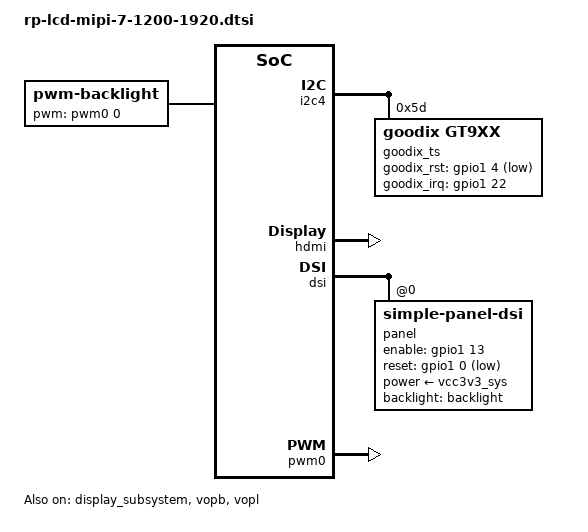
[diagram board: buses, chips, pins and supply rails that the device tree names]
#include <dt-bindings/display/drm_mipi_dsi.h>
/ {

	backlight: backlight {
		status = "okay";
		compatible = "pwm-backlight";
		pwms = <&pwm0 0 25000 0>;
		brightness-levels = <
			  0   1   2   3   4   5   6   7
			  8   9  10  11  12  13  14  15
			 16  17  18  19  20  21  22  23
			 24  25  26  27  28  29  30  31
			 32  33  34  35  36  37  38  39
			 40  41  42  43  44  45  46  47
			 48  49  50  51  52  53  54  55
			 56  57  58  59  60  61  62  63
			 64  65  66  67  68  69  70  71
			 72  73  74  75  76  77  78  79
			 80  81  82  83  84  85  86  87
			 88  89  90  91  92  93  94  95
			 96  97  98  99 100 101 102 103
			104 105 106 107 108 109 110 111
			112 113 114 115 116 117 118 119
			120 121 122 123 124 125 126 127
			128 129 130 131 132 133 134 135
			136 137 138 139 140 141 142 143
			144 145 146 147 148 149 150 151
			152 153 154 155 156 157 158 159
			160 161 162 163 164 165 166 167
			168 169 170 171 172 173 174 175
			176 177 178 179 180 181 182 183
			184 185 186 187 188 189 190 191
			192 193 194 195 196 197 198 199
			200 201 202 203 204 205 206 207
			208 209 210 211 212 213 214 215
			216 217 218 219 220 221 222 223
			224 225 226 227 228 229 230 231
			232 233 234 235 236 237 238 239
			240 241 242 243 244 245 246 247
			248 249 250 251 252 253 254 255>;
		default-brightness-level = <255>;
	};

	//bill  
        rpdzkj_config {
                compatible = "rp_config";
                user_version = "rpdzkj";
                system_rotate = "0";
                back_camera_rotate = "0";
                front_camera_rotate = "0";
                lcd_density = "280";
                language = "zh-CN";   //zh-CN //en-US
                time_zone = "Asia/Shanghai"; //Asia/Shanghai = +8   //Europe/London  = +0
                not_navigation_bar = "false";
                not_status_bar = "false";
                default_launcher = "true";
                has_root = "true";  //true//false
                usb_not_permission = "true";  
                usb_camera_only_front = "false";
                gps_use = "true";
                gps_serial_port = "/dev/ttyS4"; //UART4
                status = "okay";
        };
};




&i2c4 {
        status = "okay";
        goodix_ts@5d {
                compatible = "goodix,gt9xx";
                reg = <0x5d>;
								
		goodix_rst_gpio = <&gpio1 4 GPIO_ACTIVE_LOW>;
		goodix_irq_gpio = <&gpio1 22 IRQ_TYPE_EDGE_RISING>;

	        goodix,cfg-group0 = [
                	5C B0 04 80 07 05 45 00 02 08
									28 08 46 32 03 05 00 00 00 00
									00 00 00 00 00 00 00 8C 2C 0E
									22 24 BB 0A 00 00 02 01 03 1C
									00 01 00 00 00 00 00 32 00 00
									00 14 46 94 C5 02 00 00 00 04
									E3 16 00 B4 1D 00 8D 25 00 72
									30 00 5D 3E 00 5D 00 00 00 00
									00 00 00 00 00 00 00 00 00 00
									00 00 00 00 00 00 00 00 00 00
									00 00 00 00 00 00 00 00 00 00
									00 00 02 04 06 08 0A 0C 0E 10
									12 14 16 18 1A 1C FF FF FF FF
									FF FF FF FF FF FF FF FF FF FF
									FF FF 00 02 04 06 08 0A 0C 0F
									10 12 13 14 28 26 24 22 21 20
									1F 1E 1D 1C 18 16 FF FF FF FF
									FF 00 00 00 00 00 00 00 00 00
									00 00 00 00 B8 01];	
	        goodix,cfg-group1 = [
	                5C B0 04 80 07 05 45 00 02 08
									28 08 46 32 03 05 00 00 00 00
									00 00 00 00 00 00 00 8C 2C 0E
									22 24 BB 0A 00 00 02 01 03 1C
									00 01 00 00 00 00 00 32 00 00
									00 14 46 94 C5 02 00 00 00 04
									E3 16 00 B4 1D 00 8D 25 00 72
									30 00 5D 3E 00 5D 00 00 00 00
									00 00 00 00 00 00 00 00 00 00
									00 00 00 00 00 00 00 00 00 00
									00 00 00 00 00 00 00 00 00 00
									00 00 02 04 06 08 0A 0C 0E 10
									12 14 16 18 1A 1C FF FF FF FF
									FF FF FF FF FF FF FF FF FF FF
									FF FF 00 02 04 06 08 0A 0C 0F
									10 12 13 14 28 26 24 22 21 20
									1F 1E 1D 1C 18 16 FF FF FF FF
									FF 00 00 00 00 00 00 00 00 00
									00 00 00 00 B8 01];	
	        goodix,cfg-group2 = [
	                5C B0 04 80 07 05 45 00 02 08
									28 08 46 32 03 05 00 00 00 00
									00 00 00 00 00 00 00 8C 2C 0E
									22 24 BB 0A 00 00 02 01 03 1C
									00 01 00 00 00 00 00 32 00 00
									00 14 46 94 C5 02 00 00 00 04
									E3 16 00 B4 1D 00 8D 25 00 72
									30 00 5D 3E 00 5D 00 00 00 00
									00 00 00 00 00 00 00 00 00 00
									00 00 00 00 00 00 00 00 00 00
									00 00 00 00 00 00 00 00 00 00
									00 00 02 04 06 08 0A 0C 0E 10
									12 14 16 18 1A 1C FF FF FF FF
									FF FF FF FF FF FF FF FF FF FF
									FF FF 00 02 04 06 08 0A 0C 0F
									10 12 13 14 28 26 24 22 21 20
									1F 1E 1D 1C 18 16 FF FF FF FF
									FF 00 00 00 00 00 00 00 00 00
									00 00 00 00 B8 01];	
	        goodix,cfg-group3 = [
	                5C B0 04 80 07 05 45 00 02 08
									28 08 46 32 03 05 00 00 00 00
									00 00 00 00 00 00 00 8C 2C 0E
									22 24 BB 0A 00 00 02 01 03 1C
									00 01 00 00 00 00 00 32 00 00
									00 14 46 94 C5 02 00 00 00 04
									E3 16 00 B4 1D 00 8D 25 00 72
									30 00 5D 3E 00 5D 00 00 00 00
									00 00 00 00 00 00 00 00 00 00
									00 00 00 00 00 00 00 00 00 00
									00 00 00 00 00 00 00 00 00 00
									00 00 02 04 06 08 0A 0C 0E 10
									12 14 16 18 1A 1C FF FF FF FF
									FF FF FF FF FF FF FF FF FF FF
									FF FF 00 02 04 06 08 0A 0C 0F
									10 12 13 14 28 26 24 22 21 20
									1F 1E 1D 1C 18 16 FF FF FF FF
									FF 00 00 00 00 00 00 00 00 00
									00 00 00 00 B8 01];
	
	        goodix,cfg-group4 = [
	                5C B0 04 80 07 05 45 00 02 08
									28 08 46 32 03 05 00 00 00 00
									00 00 00 00 00 00 00 8C 2C 0E
									22 24 BB 0A 00 00 02 01 03 1C
									00 01 00 00 00 00 00 32 00 00
									00 14 46 94 C5 02 00 00 00 04
									E3 16 00 B4 1D 00 8D 25 00 72
									30 00 5D 3E 00 5D 00 00 00 00
									00 00 00 00 00 00 00 00 00 00
									00 00 00 00 00 00 00 00 00 00
									00 00 00 00 00 00 00 00 00 00
									00 00 02 04 06 08 0A 0C 0E 10
									12 14 16 18 1A 1C FF FF FF FF
									FF FF FF FF FF FF FF FF FF FF
									FF FF 00 02 04 06 08 0A 0C 0F
									10 12 13 14 28 26 24 22 21 20
									1F 1E 1D 1C 18 16 FF FF FF FF
									FF 00 00 00 00 00 00 00 00 00
									00 00 00 00 B8 01];


	        goodix,cfg-group5 = [
	                5C B0 04 80 07 05 45 00 02 08
									28 08 46 32 03 05 00 00 00 00
									00 00 00 00 00 00 00 8C 2C 0E
									22 24 BB 0A 00 00 02 01 03 1C
									00 01 00 00 00 00 00 32 00 00
									00 14 46 94 C5 02 00 00 00 04
									E3 16 00 B4 1D 00 8D 25 00 72
									30 00 5D 3E 00 5D 00 00 00 00
									00 00 00 00 00 00 00 00 00 00
									00 00 00 00 00 00 00 00 00 00
									00 00 00 00 00 00 00 00 00 00
									00 00 02 04 06 08 0A 0C 0E 10
									12 14 16 18 1A 1C FF FF FF FF
									FF FF FF FF FF FF FF FF FF FF
									FF FF 00 02 04 06 08 0A 0C 0F
									10 12 13 14 28 26 24 22 21 20
									1F 1E 1D 1C 18 16 FF FF FF FF
									FF 00 00 00 00 00 00 00 00 00
									00 00 00 00 B8 01];

        };
};
&display_subsystem {
	status = "okay";
	ports = <&vopb_out>, <&vopl_out>;
	logo-memory-region = <&drm_logo>;

	route {
		route_hdmi: route-hdmi {
			status = "okay";
			logo,uboot = "logo.bmp";
			logo,kernel = "logo_kernel.bmp";
			logo,mode = "center";
			charge_logo,mode = "center";
			connect = <&vopl_out_hdmi>;
		};

		route_dsi: route-dsi {

			status = "okay";
			//status = "disabled";
			logo,uboot = "logo.bmp";
			logo,kernel = "logo_kernel.bmp";
			logo,mode = "center";
			charge_logo,mode = "center";
			connect = <&vopb_out_dsi>;
		};

		route_dsi1: route-dsi1 {
			status = "disabled";
			logo,uboot = "logo.bmp";
			logo,kernel = "logo_kernel.bmp";
			logo,mode = "center";
			charge_logo,mode = "center";
			connect = <&vopl_out_dsi1>;
		};

		route_edp: route-edp {
			status = "disabled";
			logo,uboot = "logo.bmp";
			logo,kernel = "logo_kernel.bmp";
			logo,mode = "center";
			charge_logo,mode = "center";
			connect = <&vopb_out_edp>;
		};
	};
};


&hdmi {
        status = "okay";
        #sound-dai-cells = <0>;
        rockchip,phy-table =
                <74250000  0x8009 0x0004 0x0272>,
                <165000000 0x802b 0x0004 0x0209>,
                <297000000 0x8039 0x0005 0x028d>,
                <594000000 0x8039 0x0000 0x00f6>,
                <000000000 0x0000 0x0000 0x0000>;
};


&dsi {
        status = "okay";
        rockchip,lane-rate = <880>;

        panel {
                compatible ="simple-panel-dsi";
                status = "okay";
                reg = <0>;
		power-supply = <&vcc3v3_sys>;
                backlight = <&backlight>;
		cmd_later_reset = <0>;
                enable-gpios = <&gpio1 13 GPIO_ACTIVE_HIGH>;
		reset-gpios  = <&gpio1 0 GPIO_ACTIVE_LOW>;
                dsi,format = <MIPI_DSI_FMT_RGB888>;
                dsi,lanes = <4>;
                reset-delay-ms = <120>;
		init-delay-ms = <120>;
		enable-delay-ms = <120>;
                prepare-delay-ms = <120>;
                unprepare-delay-ms = <60>;
                disable-delay-ms = <60>;
                dsi,flags = <(MIPI_DSI_MODE_VIDEO | MIPI_DSI_MODE_VIDEO_BURST |
                              MIPI_DSI_MODE_LPM | MIPI_DSI_MODE_EOT_PACKET)>;
		
					//for king/rp/rd board cannot enable boot logo
                                        pinctrl-names = "default";
                                        pinctrl-0 = <&pwr_en>;
     		panel-init-sequence = [
              
						39 00 03 b7 50 00
						39 00 03 b8 00 00
						39 10 03 b9 00 00
						39 10 03 ba 14 42
						39 10 03 bb 03 00
						39 60 03 b9 01 00
						39 10 03 de 03 00
						39 60 03 c9 02 23
						
						39 00 02 b0 00
						39 00 06 14 08 b0 00 22 00
						39 30 02 b4 0c
						39 40 03 b6 3a d3
						39 50 02 51 e6
						39 30 02 53 2c
						
						05 78 01 29
						05 78 01 11
						
						
						39 00 03 b7 50 00
						39 00 03 b8 00 00
						39 10 03 b9 00 00
						39 10 03 ba 8c 83
						39 10 03 bb 03 00
						39 60 03 b9 01 00
						39 10 03 c9 02 23
						39 60 03 ca 01 23
						39 10 03 cb 10 05
						39 10 03 cc 05 10
						39 10 03 d0 00 00
						
						
						39 10 03 b6 03 00
						39 10 03 de 03 00
						39 10 03 d6 05 00
						39 60 03 b7 4b 02
						
						05 00 01 2c
						
      ];

      panel-exit-sequence = [
              05 00 01 28
              05 78 01 10
      ];


		display-timings {
                        native-mode = <&timing0>;
                        timing0: timing0 {
				clock-frequency = <140000000>;
                                hactive = <1200>;
                                vactive = <1920>;
                                hback-porch = <30>;	
                                hfront-porch = <60>;
                                vback-porch = <16>;
                                vfront-porch = <16>;
                                hsync-len = <4>;
                                vsync-len = <2>;
                                hsync-active = <0>;
                                vsync-active = <0>;
                                de-active = <0>;
                                pixelclk-active = <0>;
                        };
                        timing1: timing1 {
                                clock-frequency = <148000000>;
                                hactive = <1920>;
                                vactive = <1080>;
                                hback-porch = <100>;
                                hfront-porch = <160>;
                                vback-porch = <25>;
                                vfront-porch = <10>;
                                hsync-len = <20>;
                                vsync-len = <10>;
                                hsync-active = <0>;
                                vsync-active = <0>;
                                de-active = <0>;
                                pixelclk-active = <1>;
                        };
                        timing2: timing2 {
                                clock-frequency = <148000000>;
                                hactive = <1200>;
                                vactive = <1920>;
                                hback-porch = <130>;	
                                hfront-porch = <160>;
                                vback-porch = <16>;
                                vfront-porch = <16>;
                                hsync-len = <4>;
                                vsync-len = <2>;
                                hsync-active = <0>;
                                vsync-active = <0>;
                                de-active = <0>;
                                pixelclk-active = <0>;
                        };
                };
        };
};



&pwm0 {
	status = "okay";
};

&route_dsi {
	status = "okay";
};


&vopb {
        assigned-clocks = <&cru DCLK_VOP0_DIV>;
        assigned-clock-parents = <&cru PLL_CPLL>;
        //assigned-clock-parents = <&cru PLL_VPLL>;
        status = "okay";
};

&vopb_mmu {
        status = "okay";
};

&vopl {
        assigned-clocks = <&cru DCLK_VOP1_DIV>;
        assigned-clock-parents = <&cru PLL_VPLL>;
        //assigned-clock-parents = <&cru PLL_CPLL>;
        status = "okay";
};

&vopl_mmu {
        status = "okay";
};


&dsi_in_vopl {
	status = "disabled";
};
  
  &hdmi_in_vopb {
          status = "disabled";
  };
  


&edp_in_vopb { 
        status = "disabled"; 
}; 
&edp_in_vopl { 
        status = "disabled"; 
}; 

&dsi1_in_vopb { 
        status = "disabled"; 
}; 
&dsi1_in_vopl { 
        status = "disabled"; 
}; 

&pinctrl{
        pwr_5v {
                        pwr_en: pwr-en {
                                rockchip,pins = //<1 13 RK_FUNC_GPIO &pcfg_pull_up>,
                                                <4 30 RK_FUNC_GPIO &pcfg_pull_up>;
                        };
        };
};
